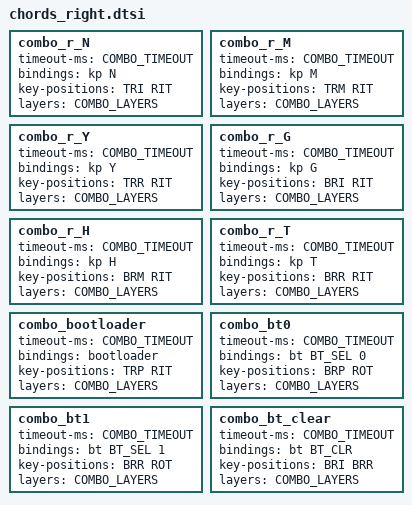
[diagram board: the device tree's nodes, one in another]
combo_r_N {
    timeout-ms = <COMBO_TIMEOUT>;
    bindings = <&kp N>;
    key-positions = <TRI RIT>;
    layers = <COMBO_LAYERS>;
};
combo_r_M {
    timeout-ms = <COMBO_TIMEOUT>;
    bindings = <&kp M>;
    key-positions = <TRM RIT>;
    layers = <COMBO_LAYERS>;
};

combo_r_Y {
    timeout-ms = <COMBO_TIMEOUT>;
    bindings = <&kp Y>;
    key-positions = <TRR RIT>;
    layers = <COMBO_LAYERS>;
};
combo_r_G {
    timeout-ms = <COMBO_TIMEOUT>;
    bindings = <&kp G>;
    key-positions = <BRI RIT>;
    layers = <COMBO_LAYERS>;
};
combo_r_H {
    timeout-ms = <COMBO_TIMEOUT>;
    bindings = <&kp H>;
    key-positions = <BRM RIT>;
    layers = <COMBO_LAYERS>;
};

combo_r_T {
    timeout-ms = <COMBO_TIMEOUT>;
    bindings = <&kp T>;
    key-positions = <BRR RIT>;
    layers = <COMBO_LAYERS>;
};
combo_bootloader {
    timeout-ms = <COMBO_TIMEOUT>;
    bindings = <&bootloader>;
    key-positions = <TRP RIT>;
    layers = <COMBO_LAYERS>;
};
combo_bt0 {
    timeout-ms = <COMBO_TIMEOUT>;
    bindings = <&bt BT_SEL 0>;
    key-positions = <BRP ROT>;
    layers = <COMBO_LAYERS>;
};
combo_bt1 {
    timeout-ms = <COMBO_TIMEOUT>;
    bindings = <&bt BT_SEL 1>;
    key-positions = <BRR ROT>;
    layers = <COMBO_LAYERS>;
};
combo_bt_clear {
    timeout-ms = <COMBO_TIMEOUT>;
    bindings = <&bt BT_CLR>;
    key-positions = <BRI BRR>;
    layers = <COMBO_LAYERS>;
};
